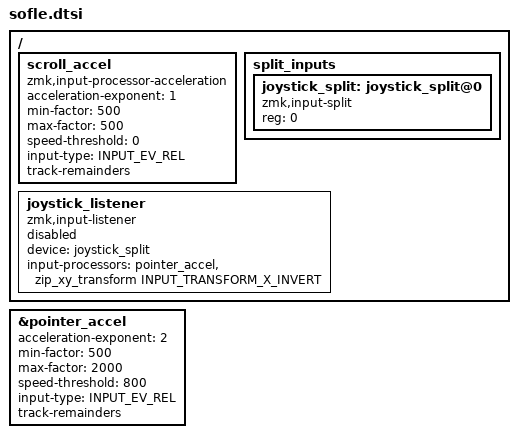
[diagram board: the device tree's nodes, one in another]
/* config/sofle.dtsi - Shared split configuration */
#include <dt-bindings/zmk/input_transform.h>
#include <input/processors.dtsi>
#include <behaviors/input_gestures_accel.dtsi>

&pointer_accel {
    /* Stay at 1.0x (base precision) until 800 cps, then ramp to 3.0x (boost) */
    acceleration-exponent = <2>;
    min-factor = <500>;
    max-factor = <2000>;
    speed-threshold = <800>;
    input-type = <INPUT_EV_REL>;
    track-remainders;
};

/ {
    scroll_accel: scroll_accel {
        compatible = "zmk,input-processor-acceleration";
        #input-processor-cells = <0>;
        /* 0.5x flat profile for scrolling */
        acceleration-exponent = <1>;
        min-factor = <500>;
        max-factor = <500>;
        speed-threshold = <0>;
        input-type = <INPUT_EV_REL>;
        track-remainders;
    };

    split_inputs {
        #address-cells = <1>;
        #size-cells = <0>;

        joystick_split: joystick_split@0 {
            compatible = "zmk,input-split";
            reg = <0>;
        };
    };

    joystick_listener: joystick_listener {
        compatible = "zmk,input-listener";
        status = "disabled";
        device = <&joystick_split>;
        input-processors = <&pointer_accel>, <&zip_xy_transform INPUT_TRANSFORM_X_INVERT>;
    };
};
